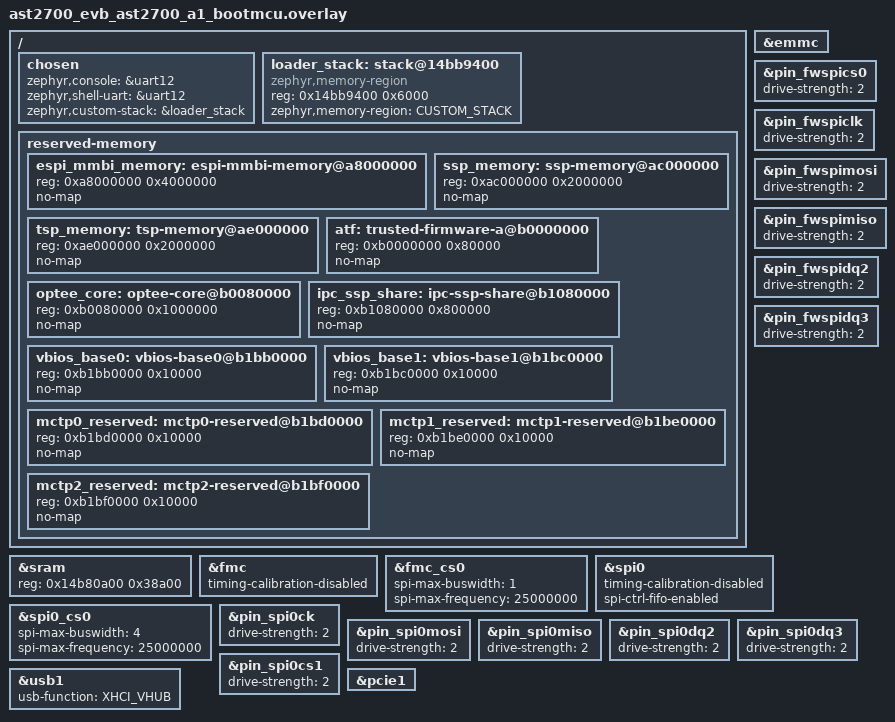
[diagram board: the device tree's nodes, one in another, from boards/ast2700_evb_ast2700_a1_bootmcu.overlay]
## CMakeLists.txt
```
# Copyright (c) 2025 ASPEED Technology Inc.
# SPDX-License-Identifier: Apache-2.0

cmake_minimum_required(VERSION 3.20.0)

find_package(Zephyr REQUIRED HINTS $ENV{ZEPHYR_BASE})
project(aspeed_irot)

zephyr_include_directories(lib/dtc/libfdt)
zephyr_include_directories(lib/xyzmodem)
zephyr_include_directories(.)

add_subdirectory(src)
add_subdirectory(soc)
add_subdirectory(lib)
```

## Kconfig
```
# Copyright (c) 2025 ASPEED Technology Inc. <chin-ting_kuo@aspeedtech.com>
# SPDX-License-Identifier: Apache-2.0

rsource "src/Kconfig"
rsource "boards/Kconfig"

module = SOC_FMC
module-str = soc-fmc
source "subsys/logging/Kconfig.template.log_config"
source "Kconfig.zephyr"
```

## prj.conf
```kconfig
# nothing here
CONFIG_ASPEED_DDR_3200=y
CONFIG_MAIN_STACK_SIZE=73728
CONFIG_LOG_MODE_IMMEDIATE=y
CONFIG_CPTRA_MANIFEST=y
CONFIG_CPTRA_MANIFEST_SIGNATURE=y
CONFIG_CRC=y
CONFIG_UART_CONSOLE=y
CONFIG_RESET=y
CONFIG_FLASH=y
CONFIG_SPI=y
CONFIG_SPI_NOR_MULTI_DEV=y
# TODO: move CONFIG_SPI_ASPEED to <Board>.conf after SPI driver for AST1040 ready
CONFIG_SPI_ASPEED=y
CONFIG_SPI_DMA_SUPPORT_ASPEED=y
CONFIG_FLASH_PAGE_LAYOUT=y
# CONFIG_SPI_NOR is not set
CONFIG_FLASH_MAP=y
CONFIG_WATCHDOG=y
CONFIG_WDT_ASPEED=y
CONFIG_HEAP_MEM_POOL_SIZE=500
CONFIG_LOG=y
```

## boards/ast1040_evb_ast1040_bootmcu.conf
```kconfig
CONFIG_SYS_LOAD_ADDR=0xf0200000
CONFIG_SSP_LOAD_ADDR=0xf0100000
CONFIG_CPTRA_MANIFEST_OFFSET=0x20000000
```

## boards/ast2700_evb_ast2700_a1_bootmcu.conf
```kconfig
CONFIG_SDHC=y
CONFIG_MMC_STACK=y
CONFIG_ASPEED_SDHCI=y
CONFIG_SLI_AST2700=y
CONFIG_SLI_TARGET_PHYCLK_1GHZ=y
CONFIG_SLI_K_ON_CPU=y
CONFIG_RESET_AST27XX=y
CONFIG_SDHC_LOG_LEVEL_OFF=y
CONFIG_CPTRA_MANIFEST_OFFSET=0x20100000
CONFIG_SYS_LOAD_ADDR=0x83000000
CONFIG_ATF_LOAD_ADDR=0xb0000000
CONFIG_OPTEE_LOAD_ADDR=0xb0080000
CONFIG_UBOOT_LOAD_ADDR=0x80000000
CONFIG_SSP_LOAD_ADDR=0xac000000
CONFIG_TSP_LOAD_ADDR=0xae000000
CONFIG_MAIN_STACK_SIZE=24576
```

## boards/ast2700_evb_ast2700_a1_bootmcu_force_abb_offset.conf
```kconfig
CONFIG_SDHC=y
CONFIG_MMC_STACK=y
CONFIG_ASPEED_SDHCI=y
CONFIG_SLI_AST2700=y
CONFIG_SLI_TARGET_PHYCLK_1GHZ=y
CONFIG_SLI_K_ON_CPU=y
CONFIG_RESET_AST27XX=y
CONFIG_SDHC_LOG_LEVEL_OFF=y
CONFIG_CPTRA_MANIFEST_OFFSET=0x20100000
CONFIG_SYS_LOAD_ADDR=0x83000000
CONFIG_ATF_LOAD_ADDR=0xb0000000
CONFIG_OPTEE_LOAD_ADDR=0xb0080000
CONFIG_UBOOT_LOAD_ADDR=0x80000000
CONFIG_SSP_LOAD_ADDR=0xac000000
CONFIG_TSP_LOAD_ADDR=0xae000000
CONFIG_FORCE_ABB_OFFSET=y
```

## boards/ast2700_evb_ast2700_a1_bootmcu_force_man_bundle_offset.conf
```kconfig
CONFIG_SDHC=y
CONFIG_MMC_STACK=y
CONFIG_ASPEED_SDHCI=y
CONFIG_SLI_AST2700=y
CONFIG_SLI_TARGET_PHYCLK_1GHZ=y
CONFIG_SLI_K_ON_CPU=y
CONFIG_RESET_AST27XX=y
CONFIG_SDHC_LOG_LEVEL_OFF=y
CONFIG_CPTRA_MANIFEST_OFFSET=0x20100000
CONFIG_SYS_LOAD_ADDR=0x83000000
CONFIG_ATF_LOAD_ADDR=0xb0000000
CONFIG_OPTEE_LOAD_ADDR=0xb0080000
CONFIG_UBOOT_LOAD_ADDR=0x80000000
CONFIG_SSP_LOAD_ADDR=0xac000000
CONFIG_TSP_LOAD_ADDR=0xae000000
CONFIG_FORCE_MANIFEST_BUNDLE_OFFSET=y
```

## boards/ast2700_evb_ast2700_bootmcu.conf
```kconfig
CONFIG_SDHC=y
CONFIG_MMC_STACK=y
CONFIG_ASPEED_SDHCI=y
CONFIG_SLI_AST2700=y
CONFIG_SLI_TARGET_PHYCLK_1GHZ=y
CONFIG_SLI_K_ON_CPU=y
CONFIG_RESET_AST27XX=y
CONFIG_SDHC_LOG_LEVEL_OFF=y
CONFIG_CPTRA_MANIFEST_OFFSET=0x20100000
CONFIG_SYS_LOAD_ADDR=0x83000000
CONFIG_ATF_LOAD_ADDR=0xb0000000
CONFIG_OPTEE_LOAD_ADDR=0xb0080000
CONFIG_UBOOT_LOAD_ADDR=0x80000000
CONFIG_SSP_LOAD_ADDR=0xac000000
CONFIG_TSP_LOAD_ADDR=0xae000000
CONFIG_MAIN_STACK_SIZE=16384
```

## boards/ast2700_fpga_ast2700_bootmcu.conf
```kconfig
CONFIG_SDHC=y
CONFIG_MMC_STACK=y
CONFIG_ASPEED_SDHCI=y
CONFIG_SLI_AST2700=y
CONFIG_SLI_TARGET_PHYCLK_1GHZ=y
CONFIG_SLI_K_ON_CPU=y
CONFIG_RESET_AST27XX=y
CONFIG_SDHC_LOG_LEVEL_OFF=y
CONFIG_CPTRA_MANIFEST_OFFSET=0x20000000
CONFIG_SYS_LOAD_ADDR=0x83000000
CONFIG_ATF_LOAD_ADDR=0xb0000000
CONFIG_OPTEE_LOAD_ADDR=0xb0080000
CONFIG_UBOOT_LOAD_ADDR=0x80000000
CONFIG_SSP_LOAD_ADDR=0xac000000
CONFIG_TSP_LOAD_ADDR=0xae000000
```

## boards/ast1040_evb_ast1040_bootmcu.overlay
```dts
/ {
	chosen {
		zephyr,console = &uart12;
		zephyr,shell-uart = &uart12;
	};

	reserved-memory {
		#address-cells = <1>;
		#size-cells = <1>;
		ranges;

		ssp_memory: ssp-memory@f0100000 {
			reg = <0xf0100000 0x2000000>;
			no-map;
			bootph-all;
		};
	};
};
```

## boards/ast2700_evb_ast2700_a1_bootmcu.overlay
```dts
/ {
	chosen {
		zephyr,console = &uart12;
		zephyr,shell-uart = &uart12;
		zephyr,custom-stack = &loader_stack;
	};

	/* sized to CONFIG_MAIN_STACK_SIZE (24KB), top kept at 0x14bbf400 */
	loader_stack: stack@14bb9400 {
		compatible = "zephyr,memory-region";
		reg = <0x14bb9400 0x6000>;
		zephyr,memory-region = "CUSTOM_STACK";
	};

	reserved-memory {
		#address-cells = <1>;
		#size-cells = <1>;
		ranges;

		espi_mmbi_memory: espi-mmbi-memory@a8000000 {
			reg = <0xa8000000 0x4000000>;
			no-map;
		};

		ssp_memory: ssp-memory@ac000000 {
			reg = <0xac000000 0x2000000>;
			no-map;
			bootph-all;
		};

		tsp_memory: tsp-memory@ae000000 {
			reg = <0xae000000 0x2000000>;
			no-map;
			bootph-all;
		};

		atf: trusted-firmware-a@b0000000 {
			reg = <0xb0000000 0x80000>;
			no-map;
			bootph-all;
		};

		optee_core: optee-core@b0080000 {
			reg = <0xb0080000 0x1000000>;
			no-map;
			bootph-all;
		};

		ipc_ssp_share: ipc-ssp-share@b1080000 {
			reg = <0xb1080000 0x800000>;
			no-map;
			bootph-all;
		};

		vbios_base0: vbios-base0@b1bb0000 {
			reg = <0xb1bb0000 0x10000>;
			no-map;
			bootph-all;
		};

		vbios_base1: vbios-base1@b1bc0000 {
			reg = <0xb1bc0000 0x10000>;
			no-map;
			bootph-all;
		};

		mctp0_reserved: mctp0-reserved@b1bd0000 {
			reg = <0xb1bd0000 0x10000>;
			no-map;
		};

		mctp1_reserved: mctp1-reserved@b1be0000 {
			reg = <0xb1be0000 0x10000>;
			no-map;
		};

		mctp2_reserved: mctp2-reserved@b1bf0000 {
			reg = <0xb1bf0000 0x10000>;
			no-map;
		};
	};
};

/* grow RAM up to loader_stack */
&sram {
	reg = <0x14b80a00 0x38a00>;
};

&emmc {
	status = "okay";
};

&fmc {
	status = "okay";
	timing-calibration-disabled;
};

&fmc_cs0 {
	status = "okay";
	spi-max-buswidth = <1>;
	spi-max-frequency = <25000000>;
};

&pin_fwspics0  { drive-strength = <2>; };
&pin_fwspiclk  { drive-strength = <2>; };
&pin_fwspimosi { drive-strength = <2>; };
&pin_fwspimiso { drive-strength = <2>; };
&pin_fwspidq2  { drive-strength = <2>; };
&pin_fwspidq3  { drive-strength = <2>; };

&spi0 {
	status = "okay";
	timing-calibration-disabled;
	spi-ctrl-fifo-enabled;
};

&spi0_cs0 {
	status = "okay";
	spi-max-buswidth = <4>;
	spi-max-frequency = <25000000>;
};

&pin_spi0ck   { drive-strength = <2>; };
&pin_spi0mosi { drive-strength = <2>; };
&pin_spi0miso { drive-strength = <2>; };
&pin_spi0dq2  { drive-strength = <2>; };
&pin_spi0dq3  { drive-strength = <2>; };
&pin_spi0cs1  { drive-strength = <2>; };

&usb1 {
	usb-function = "XHCI_VHUB";
};

&pcie1 {
	/delete-property/ ehci;
};
```

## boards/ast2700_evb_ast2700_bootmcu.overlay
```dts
/ {
	chosen {
		zephyr,console = &uart12;
		zephyr,shell-uart = &uart12;
		zephyr,custom-stack = &loader_stack;
		aspeed,peri-desc = &peri_desc;
		aspeed,dma-pool = &dma_pool;
		aspeed,usb-desc = &usb_desc;
	};

	/* sized to CONFIG_MAIN_STACK_SIZE (16KB), top kept at 0x14bbd000 */
	loader_stack: stack@14bb9000 {
		compatible = "zephyr,memory-region";
		reg = <0x14bb9000 0x4000>;
		zephyr,memory-region = "CUSTOM_STACK";
	};

	dma_pool: memory@14bbd0e0 {
		compatible = "zephyr,memory-region";
		reg = <0x14bbd0e0 0x1000>;
		zephyr,memory-region = "DMA_POOL";
	};

	peri_desc: memory@14bbe700 {
		compatible = "zephyr,memory-region";
		reg = <0x14bbe700 0x520>;
		zephyr,memory-region = "PERI_DESC";
	};

	usb_desc: memory@14bbed4c {
		compatible = "zephyr,memory-region";
		reg = <0x14bbed4c 0x154>;
		zephyr,memory-region = "USB_DESC";
	};

	reserved-memory {
		#address-cells = <1>;
		#size-cells = <1>;
		ranges;

		espi_mmbi_memory: espi-mmbi-memory@a8000000 {
			reg = <0xa8000000 0x4000000>;
			no-map;
		};

		ssp_memory: ssp-memory@ac000000 {
			reg = <0xac000000 0x2000000>;
			no-map;
			bootph-all;
		};

		tsp_memory: tsp-memory@ae000000 {
			reg = <0xae000000 0x2000000>;
			no-map;
			bootph-all;
		};

		atf: trusted-firmware-a@b0000000 {
			reg = <0xb0000000 0x80000>;
			no-map;
			bootph-all;
		};

		optee_core: optee-core@b0080000 {
			reg = <0xb0080000 0x1000000>;
			no-map;
			bootph-all;
		};

		ipc_ssp_share: ipc-ssp-share@b1080000 {
			reg = <0xb1080000 0x800000>;
			no-map;
			bootph-all;
		};

		vbios_base0: vbios-base0@b1bb0000 {
			reg = <0xb1bb0000 0x10000>;
			no-map;
			bootph-all;
		};

		vbios_base1: vbios-base1@b1bc0000 {
			reg = <0xb1bc0000 0x10000>;
			no-map;
			bootph-all;
		};

		mctp0_reserved: mctp0-reserved@b1bd0000 {
			reg = <0xb1bd0000 0x10000>;
			no-map;
		};

		mctp1_reserved: mctp1-reserved@b1be0000 {
			reg = <0xb1be0000 0x10000>;
			no-map;
		};

		mctp2_reserved: mctp2-reserved@b1bf0000 {
			reg = <0xb1bf0000 0x10000>;
			no-map;
		};
	};
};

/* grow RAM up to loader_stack */
&sram {
	reg = <0x14b80000 0x39000>;
};

&emmc {
	status = "okay";
};

&fmc {
	status = "okay";
	timing-calibration-disabled;
};

&fmc_cs0 {
	status = "okay";
	spi-max-buswidth = <1>;
	spi-max-frequency = <25000000>;
};

&pin_fwspics0  { drive-strength = <2>; };
&pin_fwspiclk  { drive-strength = <2>; };
&pin_fwspimosi { drive-strength = <2>; };
&pin_fwspimiso { drive-strength = <2>; };
&pin_fwspidq2  { drive-strength = <2>; };
&pin_fwspidq3  { drive-strength = <2>; };

/* boot watchdog, enabled by the mcu-runtime and never fed */
&wdt0 {
	status = "okay";
};
```

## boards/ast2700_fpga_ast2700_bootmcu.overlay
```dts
/ {
	chosen {
		zephyr,console = &uart12;
		zephyr,shell-uart = &uart12;
	};

	sram: memory@14b80a00 {
		reg = <0x14b80000 0x2ee00>;
	};

	reserved-memory {
		#address-cells = <1>;
		#size-cells = <1>;
		ranges;

		espi_mmbi_memory: espi-mmbi-memory@a8000000 {
			reg = <0xa8000000 0x4000000>;
			no-map;
		};

		ssp_memory: ssp-memory@ac000000 {
			reg = <0xac000000 0x2000000>;
			no-map;
			bootph-all;
		};

		tsp_memory: tsp-memory@ae000000 {
			reg = <0xae000000 0x2000000>;
			no-map;
			bootph-all;
		};

		atf: trusted-firmware-a@b0000000 {
			reg = <0xb0000000 0x80000>;
			no-map;
			bootph-all;
		};

		optee_core: optee-core@b0080000 {
			reg = <0xb0080000 0x1000000>;
			no-map;
			bootph-all;
		};

		ipc_ssp_share: ipc-ssp-share@b1080000 {
			reg = <0xb1080000 0x800000>;
			no-map;
			bootph-all;
		};

		vbios_base0: vbios-base0@b1bb0000 {
			reg = <0xb1bb0000 0x10000>;
			no-map;
			bootph-all;
		};

		vbios_base1: vbios-base1@b1bc0000 {
			reg = <0xb1bc0000 0x10000>;
			no-map;
			bootph-all;
		};

		mctp0_reserved: mctp0-reserved@b1bd0000 {
			reg = <0xb1bd0000 0x10000>;
			no-map;
		};

		mctp1_reserved: mctp1-reserved@b1be0000 {
			reg = <0xb1be0000 0x10000>;
			no-map;
		};

		mctp2_reserved: mctp2-reserved@b1bf0000 {
			reg = <0xb1bf0000 0x10000>;
			no-map;
		};
	};
};

&emmc {
	status = "okay";
};
```

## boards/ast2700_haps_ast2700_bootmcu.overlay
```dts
/ {
	chosen {
		zephyr,console = &uart12;
		zephyr,shell-uart = &uart12;
	};

	sram: memory@14b80000 {
		reg = <0x14b80000 0x2f400>;
	};

	reserved-memory {
		#address-cells = <1>;
		#size-cells = <1>;
		ranges;

		espi_mmbi_memory: espi-mmbi-memory@a8000000 {
			reg = <0xa8000000 0x4000000>;
			no-map;
		};

		ssp_memory: ssp-memory@ac000000 {
			reg = <0xac000000 0x2000000>;
			no-map;
			bootph-all;
		};

		tsp_memory: tsp-memory@ae000000 {
			reg = <0xae000000 0x2000000>;
			no-map;
			bootph-all;
		};

		atf: trusted-firmware-a@b0000000 {
			reg = <0xb0000000 0x80000>;
			no-map;
			bootph-all;
		};

		optee_core: optee-core@b0080000 {
			reg = <0xb0080000 0x1000000>;
			no-map;
			bootph-all;
		};

		ipc_ssp_share: ipc-ssp-share@b1080000 {
			reg = <0xb1080000 0x800000>;
			no-map;
			bootph-all;
		};

		vbios_base0: vbios-base0@b1bb0000 {
			reg = <0xb1bb0000 0x10000>;
			no-map;
			bootph-all;
		};

		vbios_base1: vbios-base1@b1bc0000 {
			reg = <0xb1bc0000 0x10000>;
			no-map;
			bootph-all;
		};

		mctp0_reserved: mctp0-reserved@b1bd0000 {
			reg = <0xb1bd0000 0x10000>;
			no-map;
		};

		mctp1_reserved: mctp1-reserved@b1be0000 {
			reg = <0xb1be0000 0x10000>;
			no-map;
		};

		mctp2_reserved: mctp2-reserved@b1bf0000 {
			reg = <0xb1bf0000 0x10000>;
			no-map;
		};
	};
};

&emmc {
	status = "okay";
};
```

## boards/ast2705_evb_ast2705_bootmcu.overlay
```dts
/ {
	chosen {
		zephyr,console = &uart12;
		zephyr,shell-uart = &uart12;
		zephyr,custom-stack = &loader_stack;
	};

	loader_stack: stack@14bad400 {
		compatible = "zephyr,memory-region";
		reg = <0x14bad400 0x12000>;
		zephyr,memory-region = "CUSTOM_STACK";
	};

	reserved-memory {
		#address-cells = <1>;
		#size-cells = <1>;
		ranges;

		espi_mmbi_memory: espi-mmbi-memory@a8000000 {
			reg = <0xa8000000 0x4000000>;
			no-map;
		};

		ssp_memory: ssp-memory@ac000000 {
			reg = <0xac000000 0x2000000>;
			no-map;
			bootph-all;
		};

		tsp_memory: tsp-memory@ae000000 {
			reg = <0xae000000 0x2000000>;
			no-map;
			bootph-all;
		};

		atf: trusted-firmware-a@b0000000 {
			reg = <0xb0000000 0x80000>;
			no-map;
			bootph-all;
		};

		optee_core: optee-core@b0080000 {
			reg = <0xb0080000 0x1000000>;
			no-map;
			bootph-all;
		};

		ipc_ssp_share: ipc-ssp-share@b1080000 {
			reg = <0xb1080000 0x800000>;
			no-map;
			bootph-all;
		};

		vbios_base0: vbios-base0@b1bb0000 {
			reg = <0xb1bb0000 0x10000>;
			no-map;
			bootph-all;
		};

		vbios_base1: vbios-base1@b1bc0000 {
			reg = <0xb1bc0000 0x10000>;
			no-map;
			bootph-all;
		};

		mctp0_reserved: mctp0-reserved@b1bd0000 {
			reg = <0xb1bd0000 0x10000>;
			no-map;
		};

		mctp1_reserved: mctp1-reserved@b1be0000 {
			reg = <0xb1be0000 0x10000>;
			no-map;
		};

		mctp2_reserved: mctp2-reserved@b1bf0000 {
			reg = <0xb1bf0000 0x10000>;
			no-map;
		};
	};
};

&emmc {
	status = "okay";
};
```

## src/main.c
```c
/*
 * Copyright (c) 2025 ASPEED Technology Inc.
 *
 * SPDX-License-Identifier: Apache-2.0
 */
#include <stdio.h>
#include <stdlib.h>
#include <string.h>
#include <strings.h>
#include <zephyr/device.h>
#include <zephyr/kernel.h>
#include <zephyr/sys/printk.h>
#include <zephyr/logging/log.h>
#include <soc.h>
#include <platform.h>
#include <chip.h>
#include <wdt.h>

#include "aspeed_zephyr_project_version.h"

LOG_MODULE_REGISTER(ast_soc_fmc, CONFIG_SOC_FMC_LOG_LEVEL);

int main(void)
{
	struct ast_chip *chip = NULL;
	struct ast_board *board = NULL;
	int err;

	/*
	 * Boot watchdog: it is never fed at mcu-runtime stage, so the SoC
	 * is reset once the timeout expires unless the booted image
	 * disables or takes over wdt0 at u-boot or Linux stage.
	 */
	boot_wdt_enable();

	printf("Aspeed SoC FMC %s %s (%s)\n", CONFIG_BOARD_TARGET, \
		ASPEED_ZEPHYR_PROJECT_VERSION, ASPEED_ZEPHYR_PROJECT_BUILD_TIMESTAMP);

	chip = ast_create_chip();

	if (chip) {
		board = ast_create_board(chip);

		if (board) {
			printf("Trying to boot from %s\n", board->bootmodestr);

			if (board->load_image) {
				err = board->load_image();
				if (err) {
					LOG_ERR("Failed to load image, err=%d", err);
					return err;
				}
			}

			ast_destroy_chip(chip);
		}
	}

	if (board) {
		if (board->boot)
			board->boot();

		if (board->runtime_loop)
			board->runtime_loop();
	}

	return 0;
}
```

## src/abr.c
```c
/*
 * Copyright (c) 2025 ASPEED Technology Inc.
 *
 * SPDX-License-Identifier: Apache-2.0
 */
#include <zephyr/kernel.h>
#include <zephyr/logging/log.h>
#include <string.h>
#include <abr.h>

#define WDT_ABR_CTRL            0x4c
#define WDT_ABR_INDICATOR       BIT(1)

bool abr_enabled(void)
{
	return (sys_read32(ABR_REG) & ABR_EN);
}

uint32_t abr_get_ind(void)
{
	uint32_t val;

	val = !!(sys_read32(WDTA_REG + WDT_ABR_CTRL) & WDT_ABR_INDICATOR);

	return val;
}
```

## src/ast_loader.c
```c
/*
 * Copyright (c) 2025 ASPEED Technology Inc.
 *
 * SPDX-License-Identifier: Apache-2.0
 */
#include <manifest.h>
#include <platform.h>
#include <stdio.h>
#include <stdlib.h>
#include <string.h>
#include <strings.h>
#include <zephyr/drivers/cptra.h>
#include <zephyr/logging/log.h>
#include <scu.h>
#include <ast_loader.h>
#include <chip.h>

LOG_MODULE_REGISTER(ast_loader, CONFIG_SOC_FMC_LOG_LEVEL);

struct ast_loader g_loader;

void *memcpy32(uint32_t *dst, uint32_t *src, uint32_t len)
{
	unsigned long *dl = (unsigned long *)dst;
	unsigned long *sl = (unsigned long *)src;
	char *d8, *s8;

	if (src == NULL || dst == NULL || len == 0) {
		LOG_ERR("mem_copy: src or dst is NULL or len is 0\n");
		return NULL;
	}

	if (src == dst) {
		LOG_DBG("mem_copy: src and dst are the same, no copy needed\n");
		return dst;
	}

	/* 4-byte aligned copy */
	if ((((unsigned long)dst | (unsigned long)src) & (sizeof(unsigned long) - 1)) == 0) {
		while (len >= sizeof(unsigned long)) {
			*dl++ = *sl++;
			len -= sizeof(unsigned long);
		}
	}

	/* Copy remaining bytes */
	d8 = (char *)dl;
	s8 = (char *)sl;

	while (len--)
		*d8++ = *s8++;

	return dst;
}

int ast_loader_read(uint32_t *dst, uint32_t src, uint32_t len)
{
	struct ast_loader *loader = &g_loader;
	struct ast_loader_ops *ops;
	int err = 0;

	LOG_DBG("%s: dst=0x%x, src=0x%x, len=0x%x\n", __func__, (uint32_t)dst, src, len);

	ops = ast_loader_get_ops(loader);
	if (ops && ops->copy) {
		err = ops->copy(loader, dst, src, len);
		if (err)
			return err;
	}

	return err;
}

/*
 * Chunked verification: images are hashed while they stream through the
 * staging buffer; the soc manifest is instead verified in place at dst
 * after the copy completes (its verify needs the whole structure).
 */
#ifdef CONFIG_CPTRA_MANIFEST_SIGNATURE
static int ast_loader_verify_begin(bool verify, uint32_t type)
{
	if (!verify || type == CPTRA_MANIFEST_FW_ID)
		return 0;

	return cptra_verify_image_init();
}

static int ast_loader_verify_update(bool verify, uint32_t type, uint8_t *data, uint32_t len)
{
	if (!verify || type == CPTRA_MANIFEST_FW_ID)
		return 0;

	return cptra_verify_image_update(data, len);
}

static int ast_loader_verify_final(bool verify, uint32_t type, uint32_t *dst)
{
	int err = 0;

	if (!verify)
		return 0;

	if (type == CPTRA_MANIFEST_FW_ID) {
		/*
		 * Only the A1 EVB loads the soc manifest (manifest.c); keeping the
		 * ~14KB verify frame out of other boards lets them run a 16KB stack.
		 */
#if !defined(CONFIG_CPTRA_2X_LAYOUT) && defined(CONFIG_BOARD_AST2700_EVB_AST2700_A1_BOOTMCU)
		err = cptra_verify_soc_manifest_img((struct cptra_soc_manifest *)dst);
		if (err)
			return err;

		err = cptra_verify_soc_manifest_ver((struct cptra_soc_manifest *)dst);
#endif
		return err;
	}

	return cptra_verify_image_final(type);
}

static void ast_loader_verify_abort(void)
{
	cptra_verify_image_abort();
}
#else
static int ast_loader_verify_begin(bool verify, uint32_t type)
{
	if (verify) {
		LOG_ERR("Verifier does not be registered.");
		return -1;
	}

	return 0;
}

static int ast_loader_verify_update(bool verify, uint32_t type, uint8_t *data, uint32_t len)
{
	return 0;
}

static int ast_loader_verify_final(bool verify, uint32_t type, uint32_t *dst)
{
	return 0;
}

static void ast_loader_verify_abort(void)
{
}
#endif

static void ast_loader_wipe(uint32_t *dst, uint32_t len)
{
	uint8_t *d8;

	while (len >= sizeof(uint32_t)) {
		*dst++ = 0;
		len -= sizeof(uint32_t);
	}

	d8 = (uint8_t *)dst;
	while (len--)
		*d8++ = 0;
}

/* Segmented load path for storage interfaces with random access (load_seg) */
static int _ast_loader_load_image_seg(uint32_t type, uint32_t *dst, uint32_t dst_check_max_len,
				      bool verify, uint32_t *img_read_size)
{
	struct ast_loader *loader = &g_loader;
	uint32_t seg_buf[CONFIG_AST_LOADER_SEG_BUF_SIZE / sizeof(uint32_t)];
	uint32_t off = 0, len, sz = 0;
	int err;

	if (!dst) {
		LOG_ERR("%s: Invalid input params", __func__);
		return -1;
	}

	err = loader->get_size(loader, type, &sz);
	if (err)
		return err;

	if (sz == 0) {
		LOG_WRN("Img size == 0");
		if (img_read_size)
			*img_read_size = 0;
		return 0;
	}

	if (dst_check_max_len != 0 && sz > dst_check_max_len) {
		LOG_ERR("Img size (0x%x) exceeds dst buf size (0x%x)", sz, dst_check_max_len);
		return -1;
	}

	LOG_INF("%s: type=%d, dst=0x%x, size=0x%x, sec boot verify=%d",
		__func__, type, (uint32_t)dst, sz, verify && cptra_manifest_sec_en());

	err = ast_loader_verify_begin(verify, type);
	if (err)
		return err;

	for (off = 0; off < sz; off += len) {
		len = MIN(sizeof(seg_buf), sz - off);

		err = loader->load_seg(loader, type, seg_buf, off, len);
		if (err)
			goto wipe;

		/* hash the staged bytes, not dst readback: MMIO dst may not read back */
		err = ast_loader_verify_update(verify, type, (uint8_t *)seg_buf, len);
		if (err)
			goto wipe;

		memcpy32(dst + off / sizeof(uint32_t), seg_buf, len);
	}

	err = ast_loader_verify_final(verify, type, dst);
	if (err) {
		LOG_ERR("%s: type %d verify failed, err=%d", __func__, type, err);
		goto wipe;
	}

	if (img_read_size)
		*img_read_size = sz;

	return 0;

wipe:
	/*
	 * dst held unverified data, scrub it before returning. off counts the
	 * bytes actually copied (== sz once the loop completes), so bytes never
	 * loaded at an MMIO/shared dst are left untouched.
	 */
	ast_loader_verify_abort();
	ast_loader_wipe(dst, off);
	return err;
}

/*
 * Streamed load path for recovery interfaces: the transport pushes payload
 * chunks into the sink append-only; full staging buffers are hashed and
 * copied to dst on the fly, so no whole-image buffer is needed.
 */
struct ast_loader_stage {
	uint32_t *dst;
	uint32_t max_len;
	uint32_t type;
	bool verify;
	bool hashing;
	uint32_t last_ofst;
	uint32_t received;
	uint32_t flushed;
	int err;
	uint32_t buf[CONFIG_AST_LOADER_SEG_BUF_SIZE / sizeof(uint32_t)];
};

static int ast_loader_stage_flush(struct ast_loader_stage *st, uint32_t len)
{
	int err;

	err = ast_loader_verify_update(st->verify, st->type, (uint8_t *)st->buf, len);
	if (err)
		return err;

	memcpy32(st->dst + st->flushed / sizeof(uint32_t), st->buf, len);
	st->flushed += len;

	return 0;
}

static int ast_loader_sink_write(struct ast_loader_sink *sink, uint32_t ofst,
				 const uint8_t *data, uint32_t len)
{
	struct ast_loader_stage *st = sink->priv;
	uint32_t staged, copy;
	int err;

	if (st->err)
		return st->err;

	/*
	 * A transport retry (e.g. DFU after a lost status stage) may resend the
	 * last write. Flushing is lazy, so unless that write straddled a flush
	 * it is still in the stage buffer, unhashed: overwrite it in place, like
	 * the old whole-image buffer did.
	 */
	if (len && ofst == st->last_ofst && ofst + len == st->received &&
	    ofst >= st->flushed) {
		memcpy((uint8_t *)st->buf + (ofst - st->flushed), data, len);
		return 0;
	}

	if (ofst != st->received) {
		LOG_ERR("%s: non-sequential write (ofst=0x%x, expect=0x%x)",
			__func__, ofst, st->received);
		st->err = -1;
		return -1;
	}

	if (st->max_len != 0 && st->received + len > st->max_len) {
		LOG_ERR("Img size (0x%x) exceeds dst buf size (0x%x)",
			st->received + len, st->max_len);
		st->err = -1;
		return -1;
	}

	/*
	 * Open the hash session on the first byte, not before loader->load():
	 * recovery transports may wait indefinitely for the host to start, and
	 * the session holds the Caliptra SHA HW lock.
	 *
	 * Known limitation: once open, the lock stays held until load() returns,
	 * including while a recovery host stalls between blocks (no transport
	 * has an inactivity timeout). Streaming SHA keeps its state in the
	 * engine, so the lock cannot be dropped between chunks; any other
	 * Caliptra SHA user waits for the image to finish or fail.
	 */
	if (len && !st->hashing) {
		err = ast_loader_verify_begin(st->verify, st->type);
		if (err) {
			st->err = err;
			return err;
		}
		st->hashing = true;
	}

	st->last_ofst = ofst;

	while (len) {
		staged = st->received - st->flushed;
		if (staged == sizeof(st->buf)) {
			err = ast_loader_stage_flush(st, sizeof(st->buf));
			if (err) {
				st->err = err;
				return err;
			}
			staged = 0;
		}

		copy = MIN(sizeof(st->buf) - staged, len);
		memcpy((uint8_t *)st->buf + staged, data, copy);
		st->received += copy;
		data += copy;
		len -= copy;
	}

	return 0;
}

static int _ast_loader_load_image_stream(uint32_t type, uint32_t *dst, uint32_t dst_check_max_len,
					 bool verify, uint32_t *img_read_size)
{
	struct ast_loader *loader = &g_loader;
	struct ast_loader_stage st;
	struct ast_loader_sink sink;
	uint32_t sz = 0;
	int err;

	if (!dst || !loader->load) {
		LOG_ERR("%s: Invalid input params", __func__);
		return -1;
	}

	LOG_INF("%s: type=%d, dst=0x%x, sec boot verify=%d",
		__func__, type, (uint32_t)dst, verify && cptra_manifest_sec_en());

	st.dst = dst;
	st.max_len = dst_check_max_len;
	st.type = type;
	st.verify = verify;
	st.hashing = false;
	st.last_ofst = UINT32_MAX;
	st.received = 0;
	st.flushed = 0;
	st.err = 0;

	sink.write = ast_loader_sink_write;
	sink.priv = &st;

	err = loader->load(loader, type, &sink, &sz);
	if (err || st.err) {
		err = err ? err : st.err;
		goto wipe;
	}

	if (sz == 0 && st.received == 0) {
		LOG_WRN("Img size == 0");
		if (img_read_size)
			*img_read_size = 0;
		return 0;
	}

	if (sz != st.received) {
		LOG_ERR("%s: size mismatch (reported=0x%x, received=0x%x)",
			__func__, sz, st.received);
		err = -1;
		goto wipe;
	}

	if (st.received - st.flushed) {
		err = ast_loader_stage_flush(&st, st.received - st.flushed);
		if (err)
			goto wipe;
	}

	err = ast_loader_verify_final(verify, type, dst);
	if (err) {
		LOG_ERR("%s: type %d verify failed, err=%d", __func__, type, err);
		goto wipe;
	}

	if (img_read_size)
		*img_read_size = sz;

	return 0;

wipe:
	/* destination held unverified data, scrub what was flushed to it */
	ast_loader_verify_abort();
	ast_loader_wipe(dst, st.flushed);
	return err;
}

static int _ast_loader_load(uint32_t type, uint32_t *dst, uint32_t dst_check_max_len,
			    bool verify, uint32_t *img_read_size)
{
	struct ast_loader *loader = &g_loader;

	if (loader->load_seg && loader->get_size)
		return _ast_loader_load_image_seg(type, dst, dst_check_max_len,
						  verify, img_read_size);

	return _ast_loader_load_image_stream(type, dst, dst_check_max_len,
					     verify, img_read_size);
}

/*
 * dst receives each chunk before verification completes, so every load must
 * be bounded by its destination. dst_check_max_len == 0 falls back to the
 * 64KB cap the old whole-image SRAM staging buffer imposed.
 */
int ast_loader_load_image(uint32_t type, uint32_t *dst, uint32_t dst_check_max_len, bool verify)
{
	if (dst_check_max_len == 0)
		dst_check_max_len = CONFIG_AST_LOADER_SRAM_MAX_SIZE;

	return _ast_loader_load(type, dst, dst_check_max_len, verify, NULL);
}

/*
 * Manifest images go to IME load addresses whose region sizes are unknown,
 * so stream them into the DRAM staging area at CONFIG_SYS_LOAD_ADDR first and
 * copy to dst only after verification passed: unverified data never reaches
 * dst and cannot spill into a neighbouring region.
 */
int ast_loader_load_manifest_image(uint32_t type, uint32_t *dst, bool verify, uint32_t *img_read_size)
{
	uint32_t *stage = (uint32_t *)CONFIG_SYS_LOAD_ADDR;
	uint32_t sz = 0;
	int err;

	if (!dst)
		return -1;

	err = _ast_loader_load(type, stage, CONFIG_AST_LOADER_DRAM_TEMP_BUF_MAX_SIZE,
			       verify, &sz);
	if (err)
		return err;

	if (sz)
		memcpy32(dst, stage, sz);

	if (img_read_size)
		*img_read_size = sz;

	return 0;
}

#if DT_NODE_HAS_STATUS(DT_NODELABEL(dma_pool), okay)
#define DMA_POOL_SECTION Z_GENERIC_SECTION(DMA_POOL)
#else
#define DMA_POOL_SECTION
#endif

uint8_t ast_loader_dma_pool[0x1000] DMA_POOL_SECTION;
static int ast_loader_probe(struct ast_chip *chip, struct ast_loader *loader)
{
	int err;

	loader->bootmode = chip->bootmode;
	loader->rev_id = sys_read32(SCU1_CHIP_REV_ID) & CHIP_ID_MASK;
	loader->dma_pool = ast_loader_dma_pool;

	LOG_DBG("%s: bootmode=%d\n", __func__, loader->bootmode);

	err = stor_init(loader);

	if (err == -1)
		err = recovery_init(loader);

	if (err) {
		LOG_ERR("Loader init failed %d.\n", err);
		return err;
	}

#if defined(CONFIG_CPTRA_MANIFEST_SIGNATURE) && defined(CONFIG_BOARD_AST2700_EVB_AST2700_A1_BOOTMCU)
	if (is_ast2700_a1()) {
		err = cptra_verify_abb_loader();
	}
#endif
	return err;
}

int ast_loader_init(struct ast_chip *chip)
{
	struct ast_loader *loader = &g_loader;
	int err;

	err = ast_loader_probe(chip, loader);

	return err;
}

int ast_loader_deinit(struct ast_chip *chip)
{
	struct ast_loader *loader = &g_loader;
	struct ast_loader_ops *ops;

	ops = ast_loader_get_ops(loader);
	if (ops && ops->deinit)
		return ops->deinit(loader);

	return 0;
}
```

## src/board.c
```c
/*
 * Copyright (c) 2025 ASPEED Technology Inc.
 *
 * SPDX-License-Identifier: Apache-2.0
 */
#include <platform.h>
#include <stdio.h>
#include <stdlib.h>
#include <string.h>
#include <strings.h>
#include <zephyr/logging/log.h>
#include <scu_ast2700.h>
#include <ssp_tsp_ast2700.h>
#include <manifest.h>
#include <cptra_idevid.h>
#include <zephyr/drivers/misc/aspeed/cptra_ipc.h>
#include <chip.h>

LOG_MODULE_REGISTER(ast_board, CONFIG_SOC_FMC_LOG_LEVEL);

#define ASPEED_UFS_PATH_AXI	(0x12c080e4)

static bool has_pspfw;
static bool has_sspfw;
static bool has_tspfw;

void board_manifest_image_post_process(uint32_t fw_id)
{
	uintptr_t ep = cptra_ime_get_load_addr(fw_id);
	uint64_t ep_arm = 0;

	/* convert to Arm view */
	ep_arm = ((uint64_t)ep - 0x80000000) | 0x400000000ULL;

	switch (fw_id) {
	case CPTRA_ATF_FW_ID:
		has_pspfw = true;
		sys_write32(ep_arm >> 4, SCU0_CA35_RVBAR0);
		sys_write32(ep_arm >> 4, SCU0_CA35_RVBAR1);
		sys_write32(ep_arm >> 4, SCU0_CA35_RVBAR2);
		sys_write32(ep_arm >> 4, SCU0_CA35_RVBAR3);
		break;
	case CPTRA_UBOOT_FW_ID:
		sys_write64(ep_arm, SCU0_CPU_SMP_EP0);
		break;
	case CPTRA_SSP_FW_ID:
		ssp_init(ep);
		has_sspfw = true;
		break;
	case CPTRA_TSP_FW_ID:
		tsp_init(ep);
		has_tspfw = true;
		break;
	default:
		break;
	}
}

static int board_load_image(void)
{
	int err;

	err = cptra_load_abb_image();

	return err;
}

static void board_prepare_for_boot(void)
{
	/* for v7 FPGA only to switch to uart12. */
	if (IS_ENABLED(CONFIG_ASPEED_FPGA)) {
		sys_write32(SCU0_HWSTRAP_DIS_CPU, SCU0_HW_STRAP1_CLR);
	}

	sys_write32(1, ASPEED_UFS_PATH_AXI);

	if (has_pspfw) {
		/* clean up secondary entries */
		sys_write64(0x0, SCU0_CPU_SMP_EP1);
		sys_write64(0x0, SCU0_CPU_SMP_EP2);
		sys_write64(0x0, SCU0_CPU_SMP_EP3);

		/* release CA35 reset */
		sys_write32(0x1, SCU0_CA35_REL);
	}

	/* release SSP reset */
	if (has_sspfw) {
		ssp_enable();
	}

	/* release TSP reset */
	if (has_tspfw) {
		tsp_enable();
	}
}

static const char *boot_mode_to_string(int bootmode)
{
	switch (bootmode) {
	case BOOT_DEVICE_RAM:
		return "RAM";
	case BOOT_DEVICE_MMC1:
		return "MMC1";
	case BOOT_DEVICE_SATA:
		return "SATA";
	case BOOT_DEVICE_UART:
		return "UART";
	case BOOT_DEVICE_USB:
		return "USB";
	case BOOT_DEVICE_I2C:
		return "I2C";
	case BOOT_DEVICE_I3C:
		return "I3C";
	default:
		return "UNKNOWN";
	}
}

static int board_get_boot_mode(void)
{
	uint32_t dis, strap;

	dis = sys_read32(SCU1_OTPCFG_03_02);
	strap = sys_read32(SCU1_HWSTRAP1);

	/* check if recovery is disabled by OTP */
	if (!(dis & OTPCFG2_DIS_RECOVERY_MODE)) {
		/* check if recovery is enabled by hwstrap */
		if (strap & SCU1_HWSTRAP1_EN_RECOVERY_BOOT) {
			if ((strap & SCU1_HWSTRAP1_RECOVERY_INTERFACE) == SCU1_HWSTRAP1_RECOVERY_USB)
				return BOOT_DEVICE_USB;
			else if ((strap & SCU1_HWSTRAP1_RECOVERY_INTERFACE) == SCU1_HWSTRAP1_RECOVERY_I2C)
				return BOOT_DEVICE_I2C;
			else if ((strap & SCU1_HWSTRAP1_RECOVERY_INTERFACE) == SCU1_HWSTRAP1_RECOVERY_I3C)
				return BOOT_DEVICE_I3C;
			else
				return BOOT_DEVICE_UART;
		}
	}

	if (strap & SCU1_HWSTRAP_EMMC) {
		if (strap & SCU1_HWSTRAP_UFS)
			return BOOT_DEVICE_SATA;
		else
			return BOOT_DEVICE_MMC1;
	} else {
		return BOOT_DEVICE_RAM;
	}
}

static int board_init_f(struct ast_chip	*chip, struct ast_board *board)
{
	struct peripheral *peri_tbl = chip->peripheral;
	int num = chip->peri_num;
	int err = 0;
	int i;

	if (!chip || !board) {
		LOG_ERR("Invalid chip or board pointer.\n");
		return -1;
	}

	chip->bootmode = board_get_boot_mode();
	board->bootmodestr = boot_mode_to_string(chip->bootmode);

	for (i = 0; i < num; i++) {
		if (peri_tbl[i].init) {
			LOG_DBG("%s: %s init", __func__, peri_tbl[i].name);

			err = peri_tbl[i].init(chip);
			if (err)
				LOG_ERR("%s: %s init failed.\n", __func__, peri_tbl[i].name);
		}
	}

	return err;
}

struct ast_board *ast_create_board(struct ast_chip *chip)
{
	struct ast_board *board;
	int err;

	board = malloc(sizeof(struct ast_board));
	if (!board) {
		LOG_ERR("Failed to allocate memory for ast_board");
		return NULL;
	}

	err = board_init_f(chip, board);
	if (err)
		return NULL;

	board->chip = chip;
	board->priv = NULL;
	//board->loader = chip->peripheral[3].priv;

	board->load_image = board_load_image;
	board->boot = board_prepare_for_boot;
	board->populate = cptra_populate_idevid;
	board->runtime_loop = (IS_ENABLED(CONFIG_CPTRA_IPC) ? cptra_ipc_enable : NULL);

	chip->board = board;

	return board;
}
```

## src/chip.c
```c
/*
 * Copyright (c) 2025 ASPEED Technology Inc.
 *
 * SPDX-License-Identifier: Apache-2.0
 */
#include <platform.h>
#include <stdio.h>
#include <stdlib.h>
#include <string.h>
#include <strings.h>
#include <zephyr/logging/log.h>
#include <sli.h>
#include <vga_ast2700.h>
#include <scu_ast2700.h>
#include <sdram_ast2700.h>
#include <dp_ast2700.h>
#include <pci_ast2700.h>
#include <ast_loader.h>
#include <wdt.h>
#include <extrst.h>
#include <usb.h>

LOG_MODULE_REGISTER(ast_chip, CONFIG_SOC_FMC_LOG_LEVEL);

#ifdef CONFIG_ASPEED_HAPS
#define AST2700 0
#define AST2755 1
#define AST27XX  AST2755
static int bootrom_init(struct ast_chip *chip)
{
	uint32_t i;
	uint32_t *rom = (uint32_t *)0x20300000;
	uint32_t rom_base[] = {0x14b00000, 0x14c40000};
	uint32_t rom_size[] = {0x12000, 0x8000};
	uint32_t base;

	LOG_DBG("bootrom_init\n");

#if defined(AST2755)
	sys_write32(0x0, 0x14c023d8); // map to caliptra ss 0x00000000.
#endif

	base = rom_base[AST27XX];
	for (i = 0; i < rom_size[AST27XX]/4; i++) {
	      if (i < 8)
		      LOG_DBG("rom[%d]=0x%x\n", i, rom[i]);

	      sys_write32(rom[i], (base + 4 * i));
	}

	return 0;
}

static struct peripheral peri_tbl[] = {
	{"POLICY",	NULL, NULL},//sys_policy_init},
	{"WDT",		wdt_init, NULL},
	{"EXTRST",	extrst_mask_init, NULL},
	{"LOADER",	ast_loader_init, NULL},
	{"BOOTROM",     bootrom_init, NULL},
//	{"SLI1",	sli_init_f, NULL},
//	{"DP",		dp_init, NULL},
//	{"SLI0",	sli_init_r, NULL},
	{"DRAM",	dram_init, NULL},
//	{"PCI",		pci_init, NULL},
//	{"USB",		usb_init, NULL},
};
#else
static struct peripheral peri_tbl[] = {
	{"POLICY",	NULL, NULL},//sys_policy_init},
	{"WDT",		wdt_init, NULL},
	{"EXTRST",	extrst_mask_init, NULL},
	{"LOADER",	ast_loader_init, NULL},
	{"SLI1",	sli_init_f, NULL},
	{"DP",		dp_init, NULL},
	{"SLI0",	sli_init_r, NULL},
	{"DRAM",	dram_init, NULL},
	{"PCI",		pci_init, NULL},
	{"USB",		usb_init, NULL},
};
#endif

static struct ast_chip ast_27xx = {
	.rev_id = 0,
	.peripheral = peri_tbl,
	.peri_num = ARRAY_SIZE(peri_tbl),
	.board = NULL,
};

struct ast_chip *ast_create_chip(void)
{
	struct ast_chip *chip = &ast_27xx;

	/* Put chip info here, for example scu */
	chip->scu0 = (struct ast2700_scu0 *)DT_REG_ADDR(DT_NODELABEL(syscon0));
	chip->scu1 = (struct ast2700_scu1 *)DT_REG_ADDR(DT_NODELABEL(syscon1));
	chip->rev_id = sys_read32(SCU1_CHIP_REV_ID) & CHIP_ID_MASK;
	chip->efuse = FIELD_GET(SCU_CPU_REVISION_ID_EFUSE, sys_read32(SCU0_REVISION_ID));
	chip->pcie0_enable = sys_read32(SCU0_REG + 0xa00) & BIT(0);
	chip->pcie1_enable = sys_read32(SCU0_REG + 0xa80) & BIT(0);

	return chip;
}
```

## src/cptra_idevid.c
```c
/*
 * SPDX-License-Identifier: Apache-2.0
 *
 * Copyright (c) 2025 ASPEED Technology Inc.
 */

#include <zephyr/drivers/cptra.h>
#include <zephyr/logging/log.h>
#include <zephyr/drivers/misc/aspeed/otp_ast27xx.h>
#include <zephyr/sys/byteorder.h>
#include <zephyr/sys/util.h>
#include <platform.h>
#include <chip.h>
#include <scu.h>
#include <manifest.h>

LOG_MODULE_REGISTER(cptra_idevid, CONFIG_SOC_LOG_LEVEL);

#if defined(CONFIG_CPTRA_DICE)
#define CPTRA_DICE_DRV_NAME			DEVICE_DT_NAME(DT_INST(0, aspeed_cptra_dice))
#else
#define CPTRA_DICE_DRV_NAME			"aspeed_cptra_dice"
#endif

#define CPTRA_MISC_DRV_NAME			DEVICE_DT_NAME(DT_INST(0, aspeed_cptra_misc))

/*
 * FMC/RT release tag lookup table, keyed on runtime_sha384_digest[0..1]
 * (first 8 bytes of the 48-byte RT firmware SHA384).
 *
 * To add a new entry: run cptra_dump_fw_info() on real hardware, copy the
 * "RT sha384" hex dump first 8 bytes, and add a row here.
 *
 * Release list: https://github.com/chipsalliance/caliptra-sw#fmcruntime-fw-releases
 */
struct cptra_fw_tag_entry {
	uint32_t rt_sha384[2]; /* runtime_sha384_digest[0..1], little-endian */
	const char *tag;
};

static const struct cptra_fw_tag_entry cptra_fw_tag_table[] = {
	/*
	 * Keys: runtime_sha384_digest[0..1] as little-endian uint32.
	 * Source: first 16 hex chars of runtime SHA384 per release at
	 * https://github.com/chipsalliance/caliptra-sw#fmcruntime-fw-releases
	 * Verify with "Caliptra RT  sha384:" hex dump logged at boot.
	 */
	{ .rt_sha384 = { 0x002809d7, 0x387f0bc6 }, .tag = "rt-1.2.0" }, /* d7092800c60b7f38 */
	{ .rt_sha384 = { 0xb6838fd4, 0x328d3729 }, .tag = "rt-1.2.1" }, /* d48f83b629378d32 */
	{ .rt_sha384 = { 0x09ce915a, 0x76c9e8d7 }, .tag = "rt-1.2.2" }, /* 5a91ce09d7e8c976 */
	{ .rt_sha384 = { 0x89865e07, 0x491547ec }, .tag = "rt-1.2.3" }, /* 075e8689ec471549 */
	{ .rt_sha384 = { 0x4aac73bf, 0xe46d0999 }, .tag = "rt-1.2.4" }, /* bf73ac4a99096de4 */
	{ .rt_sha384 = { 0x67406db5, 0x1e0a2315 }, .tag = "rt-1.2.5" }, /* b56d406715230a1e */
	{ .rt_sha384 = { 0xe59fd0ae, 0xa3263499 }, .tag = "rt-1.3.0" }, /* aed09fe5993426a3 */
};

static const char *cptra_lookup_fw_tag(const uint32_t *rt_sha384)
{
	for (int i = 0; i < ARRAY_SIZE(cptra_fw_tag_table); i++) {
		if (cptra_fw_tag_table[i].rt_sha384[0] == rt_sha384[0] &&
		    cptra_fw_tag_table[i].rt_sha384[1] == rt_sha384[1])
			return cptra_fw_tag_table[i].tag;
	}
	return NULL;
}

static void cptra_dump_fw_info(void)
{
	const struct device *dev = device_get_binding(CPTRA_MISC_DRV_NAME);
	struct cptra_fw_info_ia in = {};
	struct cptra_fw_info_oa out = {};
	char sha_str[41]; /* 20 bytes → 40 hex chars + NUL */
	const char *tag;
	int ret;

	if (!dev) {
		LOG_WRN("cptra fw_info: misc device not found");
		return;
	}

	ret = caliptra_fw_info(dev, &in, &out);
	if (ret) {
		LOG_WRN("cptra fw_info: mailbox failed, ret:%d", ret);
		return;
	}

	bin2hex(out.runtime_revision, sizeof(out.runtime_revision), sha_str, sizeof(sha_str));
	tag = cptra_lookup_fw_tag(out.runtime_sha384_digest);
	if (tag)
		LOG_INF("Caliptra RT revision: %s (%s)", sha_str, tag);
	else
		LOG_INF("Caliptra RT revision: %s", sha_str);
}

#define OTPCAL_IDEVID_TBS_OFFSET		0x62
#define OTPCAL_IDEVID_SIGN_OFFSET		0x262

#if defined(CONFIG_CPTRA_DICE)
static int cptra_get_idevid_cert(struct cptra_get_idev_cert_ia *input,
				 struct cptra_get_idev_cert_oa *output)
{
	const struct device *dev = device_get_binding(CPTRA_DICE_DRV_NAME);
	uint32_t cert_offset = OTPCAL_IDEVID_SIGN_OFFSET;
	uint32_t tbs_offset = OTPCAL_IDEVID_TBS_OFFSET;
	uint16_t *p16 = (uint16_t *)input->tbs;
	uint16_t data;
	int tbs_size = 0;
	int ret;

	if (!dev) {
		LOG_ERR("Device %s not found", CPTRA_DICE_DRV_NAME);
		return -ENODEV;
	}

	LOG_INF("Get IDEVID Certificate");
	memset(input, 0, sizeof(struct cptra_get_idev_cert_ia));
	memset(output, 0, sizeof(struct cptra_get_idev_cert_oa));

	LOG_INF("Get tbs from OTP");

	/* Check TBS tag */
	ret = otp_read_cptra(tbs_offset, &data);
	if (ret) {
		LOG_ERR("otp_read_cptra failed, ret:0x%x", ret);
		goto end;
	}

	if (data == 0x0) {
		LOG_WRN("tbs is empty");
		ret = -EIO;
		goto end;

	} else if (data != 0x8230) {
		LOG_ERR("Invalid tbs tag, expected 0x8230, got 0x%x", data);
		ret = -EIO;
		goto end;
	}

	/* Check TBS length */
	ret = otp_read_cptra(tbs_offset + 1, &data);
	if (ret) {
		LOG_ERR("otp_read_cptra failed, ret:0x%x", ret);
		goto end;
	}

	tbs_size = sys_cpu_to_be16(data);
	LOG_INF("tbs size: 0x%x", tbs_size);
	if (tbs_size >= sizeof(input->tbs)) {
		LOG_ERR("Invalid tbs length, expected less than 0x%x, got 0x%x",
			sizeof(input->tbs), data);
		ret = -EIO;
		goto end;
	}

	// TBS includes ASN.1 tag
	for (int i = 0; i < ((tbs_size + 1) / 2) + 2; i++) {
		ret = otp_read_cptra(tbs_offset + i, p16++);
		if (ret) {
			LOG_ERR("otp_read_cptra failed, ret:0x%x", ret);
			goto end;
		}
	}

	input->tbs_size = tbs_size + 0x4; /* 4 bytes for DER TAG & LENGTH */
	/* LOG_HEXDUMP_INF(input->tbs, input->tbs_size, "tbs"); */

	LOG_INF("Get signature_r from OTP");
	p16 = (uint16_t *)input->signature_r;
	for (int i = 0; i < sizeof(input->signature_r) / 2; i++) {
		ret = otp_read_cptra(cert_offset + i, p16++);
		if (ret) {
			LOG_ERR("otp_read_cptra failed, ret:0x%x", ret);
			goto end;
		}
	}

	cert_offset += 0x18; /* 48 bytes for r */
	LOG_INF("Get signature_s from OTP");
	p16 = (uint16_t *)input->signature_s;
	for (int i = 0; i < sizeof(input->signature_s) / 2; i++) {
		ret = otp_read_cptra(cert_offset + i, p16++);
		if (ret) {
			LOG_ERR("otp_read_cptra failed, ret:0x%x", ret);
			goto end;
		}
	}

	/* LOG_HEXDUMP_INF(input->signature_r, sizeof(input->signature_r), "r:"); */
	/* LOG_HEXDUMP_INF(input->signature_s, sizeof(input->signature_s), "s:"); */

	LOG_INF("Get IDEVID Certificate from Cptra");
	ret = caliptra_get_idev_cert(dev, input, output);
	if (ret) {
		LOG_ERR("caliptra_get_idev_cert is failure, ret:0x%x", ret);
		goto end;
	} else
		LOG_DBG("caliptra_get_idev_cert is successful");

	LOG_DBG("output: chksum:0x%x, fips_status:0x%x",
		output->chksum, output->fips_status);
	LOG_HEXDUMP_DBG(output->cert, output->cert_size, "cert:");

	return 0;

end:
	return ret;
}

static int cptra_populate_idevid(void)
{

	const struct device *dev = device_get_binding(CPTRA_DICE_DRV_NAME);
	struct cptra_get_idev_cert_ia input;
	struct cptra_get_idev_cert_oa output;
	struct cptra_populate_idev_cert_ia in_buff;
	struct cptra_populate_idev_cert_oa out_buff;
	int ret;

	if (!dev) {
		LOG_ERR("Device %s not found", CPTRA_DICE_DRV_NAME);
		return -ENODEV;
	}

	/* Get IDEVID Certificate */
	ret = cptra_get_idevid_cert(&input, &output);
	if (ret)
		return ret;

	/* Populate IDEVID Certificate */
	LOG_INF("Populate IDEVID Certificate...");

	memset(&in_buff, 0, sizeof(struct cptra_populate_idev_cert_ia));
	memset(&out_buff, 0, sizeof(struct cptra_populate_idev_cert_oa));

	/* Initial idevid cert */
	in_buff.cert_size = output.cert_size;
	memcpy(in_buff.cert, output.cert, output.cert_size);

	ret = caliptra_populate_idev_cert(dev, &in_buff, &out_buff);
	if (ret) {
		LOG_ERR("caliptra_populate_idev_cert is failure, ret:0x%x", ret);
		goto end;
	} else
		LOG_DBG("caliptra_populate_idev_cert is successful");

	LOG_DBG("output: chksum:0x%x, fips_status:0x%x",
		out_buff.chksum, out_buff.fips_status);

	if (out_buff.fips_status) {
		LOG_ERR("FIPS status is not zero, fips_status:0x%x",
			out_buff.fips_status);
		ret = -EIO;
		goto end;
	}

	LOG_INF("%s: Pass", __func__);
	return 0;

end:
	LOG_ERR("%s: Failed", __func__);
	return ret;
}
#endif /* CONFIG_CPTRA_DICE */

#define CPTRA_IFC_BASE			DT_REG_ADDR(DT_NODELABEL(cptra_ifc))


static void cptra_check_error(void)
{
	uint32_t hw_fatal    = sys_read32(CPTRA_IFC_BASE + CPTRA_HW_ERROR_FATAL);
	uint32_t hw_nonfatal = sys_read32(CPTRA_IFC_BASE + CPTRA_HW_ERROR_NONFATAL);
	uint32_t fw_fatal    = sys_read32(CPTRA_IFC_BASE + CPTRA_FW_ERROR_FATAL);
	uint32_t fw_nonfatal = sys_read32(CPTRA_IFC_BASE + CPTRA_FW_ERROR_NONFATAL);

	if (hw_fatal || hw_nonfatal || fw_fatal || fw_nonfatal)
		LOG_WRN("CPTRA errors: hw_fatal=0x%08x hw_nonfatal=0x%08x fw_fatal=0x%08x fw_nonfatal=0x%08x",
			hw_fatal, hw_nonfatal, fw_fatal, fw_nonfatal);
	else
		LOG_INF("CPTRA: no errors detected");
}

int cptra_otp_init(struct ast_chip *chip)
{
	if (sys_read32(SCU1_HWSTRAP1) & SCU1_HWSTRAP1_DIS_CPTRA) {
		LOG_WRN("Caliptra is disabled");
		return 0;
	}

	cptra_check_error();

	if (!(sys_read32(SCU1_CPTRA_CTRL) & SCU1_CPTRA_RDY_FOR_RT)) {
		LOG_WRN("Caliptra is unavailable");
		return 0;
	}

	cptra_dump_fw_info();

#if !defined(CONFIG_CPTRA_DICE)
	return 0;
#else
	const struct device *dev = device_get_binding(CPTRA_DICE_DRV_NAME);
	struct cptra_reallocate_dpe_context_limits_ia input;
	struct cptra_reallocate_dpe_context_limits_oa output;
	int ret;

	ret = cptra_populate_idevid();
	if (ret)
		LOG_WRN("populate idevid skipped, ret:%d", ret);

	if (!dev) {
		LOG_ERR("Device %s not found", CPTRA_DICE_DRV_NAME);
		return -ENODEV;
	}

	memset(&input, 0, sizeof(input));
	memset(&output, 0, sizeof(output));
	input.pl0_context_limit = 32;

	if (!is_ast2700_a1()) {
		ret = caliptra_reallocate_dpe_context_limits(dev, &input, &output);
		if (ret) {
			LOG_ERR("caliptra_reallocate_dpe_context_limits failed, ret:0x%x", ret);
			return 0;
		}

		LOG_INF("DPE context limits reallocated: pl0=%u, pl1=%u",
			output.new_pl0_context_limit, output.new_pl1_context_limit);
	}

	return 0;
#endif
}
```

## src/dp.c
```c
/*
 * Copyright (c) 2025 ASPEED Technology Inc.
 *
 * SPDX-License-Identifier: Apache-2.0
 */
#include <errno.h>
#include <zephyr/types.h>
#include <zephyr/sys/sys_io.h>
#include <zephyr/sys/util.h>
#include <zephyr/device.h>
#include <zephyr/kernel.h>
#include <zephyr/logging/log.h>
#include <platform.h>
#include <dp_ast2700.h>
#include <scu_ast2700.h>
#include <chip.h>

LOG_MODULE_REGISTER(dp, CONFIG_SOC_FMC_LOG_LEVEL);

int dp_init(struct ast_chip *chip)
{
	struct ast2700_scu0 *scu = chip->scu0;
	uint32_t mcu_ctrl, val;
	uintptr_t scu_offset;
	bool is_mcu_stop = false;

	val = scu->vga_func_ctrl;
	scu_offset = (((val >> 8) & 0x3) == 1)
		   ? (uintptr_t)&scu->vga1_scratch1[0] : (uintptr_t)&scu->vga0_scratch1[0];
	val = sys_read32(scu_offset);
	is_mcu_stop = ((val & BIT(13)) == 0);

	/* reset for DPTX and DPMCU if MCU isn't running */
	if (is_mcu_stop) {
		LOG_DBG("%s: reset DP & MCU", __func__);
		setbits_le32(&scu->modrst1_ctrl, SCU0_RST_DP);
		setbits_le32(&scu->modrst1_ctrl, SCU0_RST_DPMCU);
		k_usleep(100);

		// enable clk
		setbits_le32(&scu->clkgate_clr, SCU0_CLKGATE1_DP);
		k_msleep(10);

		setbits_le32(&scu->modrst1_clr, SCU0_RST_DP);
		setbits_le32(&scu->modrst1_clr, SCU0_RST_DPMCU);
		k_usleep(1);
	}

	val = sys_read32(DP_VERSION);
	if (val == 0) {
		printf("%s: Can't access DP, version(%x)\n", __func__, val);
		return -1;
	}

	/* select HOST or BMC as display control master
	 * enable or disable sending EDID to Host
	 */
	val = sys_read32(DP_HANDSHAKE);
	val &= ~(DP_HANDSHAKE_HOST_READ_EDID | DP_HANDSHAKE_VIDEO_FMT_SRC);
	sys_write32(val, DP_HANDSHAKE);

	/* DPMCU */
	/* clear display format and enable region */
	sys_write32(0, (MCU_DMEM_BASE + 0x0de0));

	/* load DPMCU firmware to internal instruction memory */
	if (is_mcu_stop) {
		LOG_DBG("%s: DPMCU fw loaded", __func__);
		mcu_ctrl = MCU_CTRL_CONFIG | MCU_CTRL_IMEM_CLK_OFF | MCU_CTRL_IMEM_SHUT_DOWN |
		      MCU_CTRL_DMEM_CLK_OFF | MCU_CTRL_DMEM_SHUT_DOWN | MCU_CTRL_AHBS_SW_RST;
		sys_write32(mcu_ctrl, MCU_CTRL);

		mcu_ctrl &= ~(MCU_CTRL_IMEM_SHUT_DOWN | MCU_CTRL_DMEM_SHUT_DOWN);
		sys_write32(mcu_ctrl, MCU_CTRL);

		mcu_ctrl &= ~(MCU_CTRL_IMEM_CLK_OFF | MCU_CTRL_DMEM_CLK_OFF);
		sys_write32(mcu_ctrl, MCU_CTRL);

		mcu_ctrl |= MCU_CTRL_AHBS_IMEM_EN;
		sys_write32(mcu_ctrl, MCU_CTRL);

		ast_loader_load_image(CPTRA_DP_FW_FW_ID, (uint32_t *)MCU_IMEM_BASE, 0);

		/* release DPMCU internal reset */
		mcu_ctrl &= ~MCU_CTRL_AHBS_IMEM_EN;
		sys_write32(mcu_ctrl, MCU_CTRL);
		mcu_ctrl |= MCU_CTRL_CORE_SW_RST | MCU_CTRL_AHBM_SW_RST;
		sys_write32(mcu_ctrl, MCU_CTRL);
		//disable dp interrupt
		sys_write32(FIELD_PREP(MCU_INTR_CTRL_EN, 0xff), MCU_INTR_CTRL);
	}

	//set vga ASTDP with DPMCU FW handling scratch
	val = sys_read32(scu_offset);
	val &= ~(0x7 << 9);
	val |= 0x7 << 9;
	sys_write32(val, (uintptr_t)&scu->vga0_scratch1[0]);
	sys_write32(val, (uintptr_t)&scu->vga1_scratch1[0]);

	return 0;
}
```

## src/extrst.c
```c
/*
 * Copyright (c) 2025 ASPEED Technology Inc.
 *
 * SPDX-License-Identifier: Apache-2.0
 */
#include <platform.h>
#include <stdio.h>
#include <stdlib.h>
#include <zephyr/kernel.h>
#include <extrst.h>

int extrst_mask_init(struct ast_chip *chip)
{
        uint32_t reg;

        /* only init EXTRST mask during power on reset */
        reg = sys_read32(SCU0_RESET_LOG1);
        if (!(reg & BIT(0)))
                return 0;

	sys_write32(SCU0_EXTRST_MASK_1_VAL, (SCU0_REG + 0x2F0));
	sys_write32(SCU0_EXTRST_MASK_2_VAL, (SCU0_REG + 0x2F4));

	sys_write32(SCU1_EXTRST_MASK_1_VAL, (SCU1_REG + 0x2F0));
	sys_write32(SCU1_EXTRST_MASK_2_VAL, (SCU1_REG + 0x2F4));
	sys_write32(SCU1_EXTRST_MASK_3_VAL, (SCU1_REG + 0x2F8));

	if (sys_read32(SCU1_HW_STRAP1) & BIT(3)) {
		reg = sys_read32((SCU1_REG + 0x2F4)) | BIT(1);
		sys_write32(reg, (SCU1_REG + 0x2F4));
	}

        return 0;
}
```
